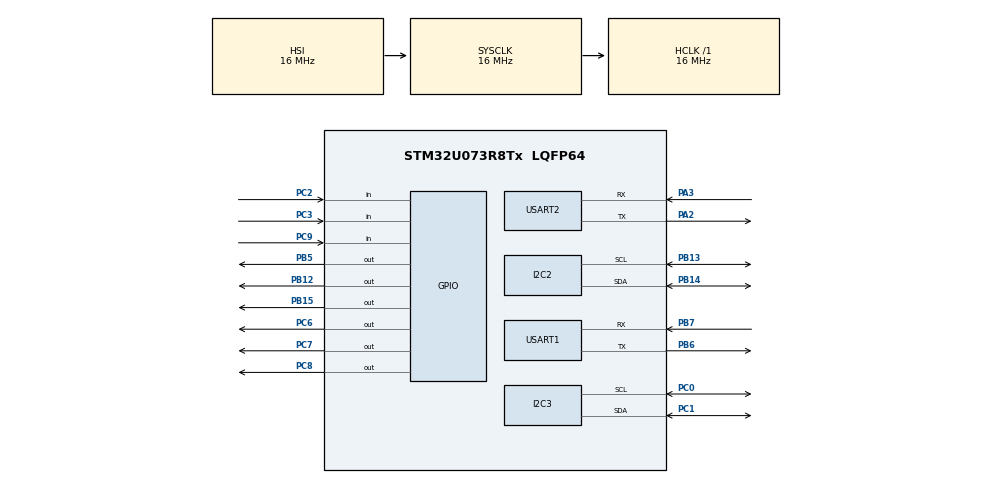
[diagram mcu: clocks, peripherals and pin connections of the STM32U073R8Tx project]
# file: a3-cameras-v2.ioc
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I2C2.Timing=0x00303D5B
I2C3.Timing=0x00303D5B
Mcu.Family=STM32U0
Mcu.Name=STM32U073R8Tx
Mcu.Package=LQFP64
NVIC.PriorityGroup=NVIC_PRIORITYGROUP_2
NVIC.TIM1_BRK_UP_TRG_COM_IRQn=true\:3\:0\:false\:false\:true\:false\:false\:true\:true
NVIC.TimeBase=TIM1_BRK_UP_TRG_COM_IRQn
NVIC.TimeBaseIP=TIM1
PA13\ (SWDIO).Mode=Serial_Wire
PA13\ (SWDIO).Signal=DEBUG_JTMS-SWDIO
PA14\ (SWCLK).Mode=Serial_Wire
PA14\ (SWCLK).Signal=DEBUG_JTCK-SWCLK
PA2.Mode=Asynchronous
PA2.Signal=USART2_TX
PA3.Mode=Asynchronous
PA3.Signal=USART2_RX
PB12.Signal=GPIO_Output
PB13.Mode=I2C
PB13.Signal=I2C2_SCL
PB14.Mode=I2C
PB14.Signal=I2C2_SDA
PB15.Signal=GPIO_Output
PB5.Signal=GPIO_Output
PB6.Mode=Asynchronous
PB6.Signal=USART1_TX
PB7.Mode=Asynchronous
PB7.Signal=USART1_RX
PC0.Mode=I2C
PC0.Signal=I2C3_SCL
PC1.Mode=I2C
PC1.Signal=I2C3_SDA
PC2.Signal=GPIO_Input
PC3.Signal=GPIO_Input
PC6.Signal=GPIO_Output
PC7.Signal=GPIO_Output
PC8.Signal=GPIO_Output
PC9.Signal=GPIO_Input
ProjectManager.HeapSize=0x200
ProjectManager.StackSize=0x400
ProjectManager.TargetToolchain=CMake
RCC.AHBFreq_Value=16000000
RCC.CortexFreq_Value=16000000
RCC.HCLKFreq_Value=16000000
RCC.HSE_VALUE=4000000
RCC.HSI48_VALUE=48000000
RCC.HSI_VALUE=16000000
RCC.LSE_VALUE=32768
RCC.MSI_VALUE=4000000
RCC.SYSCLKFreq_VALUE=16000000
RCC.VCOOutputFreq_Value=64000000
USART1.VirtualMode-Asynchronous=VM_ASYNC
USART2.VirtualMode-Asynchronous=VM_ASYNC
VP_PWR_VS_SECSignals.Mode=Security/Privilege
VP_SYS_VS_tim1.Mode=TIM1
VP_THREADX_VS_RTOSJjThreadXJjCoreJjDefault.Mode=Core_Default
board=custom

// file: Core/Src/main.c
/* USER CODE BEGIN Header */
/**
  ******************************************************************************
  * @file           : main.c
  * @brief          : Main program body
  ******************************************************************************
  * @attention
  *
  * Copyright (c) 2026 STMicroelectronics.
  * All rights reserved.
  *
  * This software is licensed under terms that can be found in the LICENSE file
  * in the root directory of this software component.
  * If no LICENSE file comes with this software, it is provided AS-IS.
  *
  ******************************************************************************
  */
/* USER CODE END Header */
#include "app_threadx.h"
#include "main.h"

/* USER CODE BEGIN Includes */
#include "common.h"
#include "pmic.h"

/* USER CODE END Includes */

I2C_HandleTypeDef hi2c2;
I2C_HandleTypeDef hi2c3;

UART_HandleTypeDef huart1;
UART_HandleTypeDef huart2;

/* USER CODE BEGIN PV */

LED_Status_T LED_STATUS = LED_NOMINAL;

/* USER CODE END PV */

void SystemClock_Config(void);
static void MX_GPIO_Init(void);
static void MX_I2C2_Init(void);
static void MX_I2C3_Init(void);
static void MX_USART1_UART_Init(void);
static void MX_USART2_UART_Init(void);

/* USER CODE BEGIN 0 */

/* Wrapper so other modules pmic.c can re-init UART1 to solve residual voltage issue */
void soc_uart_reinit(void)
{
    MX_USART1_UART_Init();
}

/* USER CODE END 0 */

int main(void)
{

  /* MCU Configuration--------------------------------------------------------*/

  /* Reset of all peripherals, Initializes the Flash interface and the Systick. */
  HAL_Init();

  /* Configure the system clock */
  SystemClock_Config();

  /* Initialize all configured peripherals */
  MX_GPIO_Init();
  MX_I2C2_Init();
  MX_I2C3_Init();
  MX_USART1_UART_Init();
  MX_USART2_UART_Init();

  MX_ThreadX_Init();

  /* We should never get here as control is now taken by the scheduler */

  /* Infinite loop */
  while (1)
  {

  }
}

void SystemClock_Config(void)
{
  RCC_OscInitTypeDef RCC_OscInitStruct = {0};
  RCC_ClkInitTypeDef RCC_ClkInitStruct = {0};

  /** Configure the main internal regulator output voltage
  */
  HAL_PWREx_ControlVoltageScaling(PWR_REGULATOR_VOLTAGE_SCALE2);

  /** Initializes the RCC Oscillators according to the specified parameters
  * in the RCC_OscInitTypeDef structure.
  */
  RCC_OscInitStruct.OscillatorType = RCC_OSCILLATORTYPE_HSI;
  RCC_OscInitStruct.HSIState = RCC_HSI_ON;
  RCC_OscInitStruct.HSICalibrationValue = RCC_HSICALIBRATION_DEFAULT;
  RCC_OscInitStruct.PLL.PLLState = RCC_PLL_NONE;
  if (HAL_RCC_OscConfig(&RCC_OscInitStruct) != HAL_OK)
  {
    Error_Handler();
  }

  /** Initializes the CPU, AHB and APB buses clocks
  */
  RCC_ClkInitStruct.ClockType = RCC_CLOCKTYPE_HCLK|RCC_CLOCKTYPE_SYSCLK
                              |RCC_CLOCKTYPE_PCLK1;
  RCC_ClkInitStruct.SYSCLKSource = RCC_SYSCLKSOURCE_HSI;
  RCC_ClkInitStruct.AHBCLKDivider = RCC_SYSCLK_DIV1;
  RCC_ClkInitStruct.APB1CLKDivider = RCC_HCLK_DIV1;

  if (HAL_RCC_ClockConfig(&RCC_ClkInitStruct, FLASH_LATENCY_1) != HAL_OK)
  {
    Error_Handler();
  }
}

static void MX_I2C2_Init(void)
{

  hi2c2.Instance = I2C2;
  hi2c2.Init.Timing = 0x00303D5B;
  hi2c2.Init.OwnAddress1 = 0;
  hi2c2.Init.AddressingMode = I2C_ADDRESSINGMODE_7BIT;
  hi2c2.Init.DualAddressMode = I2C_DUALADDRESS_DISABLE;
  hi2c2.Init.OwnAddress2 = 0;
  hi2c2.Init.OwnAddress2Masks = I2C_OA2_NOMASK;
  hi2c2.Init.GeneralCallMode = I2C_GENERALCALL_DISABLE;
  hi2c2.Init.NoStretchMode = I2C_NOSTRETCH_DISABLE;
  if (HAL_I2C_Init(&hi2c2) != HAL_OK)
  {
    Error_Handler();
  }

  /** Configure Analogue filter
  */
  if (HAL_I2CEx_ConfigAnalogFilter(&hi2c2, I2C_ANALOGFILTER_ENABLE) != HAL_OK)
  {
    Error_Handler();
  }

  /** Configure Digital filter
  */
  if (HAL_I2CEx_ConfigDigitalFilter(&hi2c2, 0) != HAL_OK)
  {
    Error_Handler();
  }

}

static void MX_I2C3_Init(void)
{

  hi2c3.Instance = I2C3;
  hi2c3.Init.Timing = 0x00303D5B;
  hi2c3.Init.OwnAddress1 = 0;
  hi2c3.Init.AddressingMode = I2C_ADDRESSINGMODE_7BIT;
  hi2c3.Init.DualAddressMode = I2C_DUALADDRESS_DISABLE;
  hi2c3.Init.OwnAddress2 = 0;
  hi2c3.Init.OwnAddress2Masks = I2C_OA2_NOMASK;
  hi2c3.Init.GeneralCallMode = I2C_GENERALCALL_DISABLE;
  hi2c3.Init.NoStretchMode = I2C_NOSTRETCH_DISABLE;
  if (HAL_I2C_Init(&hi2c3) != HAL_OK)
  {
    Error_Handler();
  }

  /** Configure Analogue filter
  */
  if (HAL_I2CEx_ConfigAnalogFilter(&hi2c3, I2C_ANALOGFILTER_ENABLE) != HAL_OK)
  {
    Error_Handler();
  }

  /** Configure Digital filter
  */
  if (HAL_I2CEx_ConfigDigitalFilter(&hi2c3, 0) != HAL_OK)
  {
    Error_Handler();
  }

}

static void MX_USART1_UART_Init(void)
{

  huart1.Instance = USART1;
  huart1.Init.BaudRate = 115200;
  huart1.Init.WordLength = UART_WORDLENGTH_8B;
  huart1.Init.StopBits = UART_STOPBITS_1;
  huart1.Init.Parity = UART_PARITY_NONE;
  huart1.Init.Mode = UART_MODE_TX_RX;
  huart1.Init.HwFlowCtl = UART_HWCONTROL_NONE;
  huart1.Init.OverSampling = UART_OVERSAMPLING_16;
  huart1.Init.OneBitSampling = UART_ONE_BIT_SAMPLE_DISABLE;
  huart1.Init.ClockPrescaler = UART_PRESCALER_DIV1;
  huart1.AdvancedInit.AdvFeatureInit = UART_ADVFEATURE_NO_INIT;
  if (HAL_UART_Init(&huart1) != HAL_OK)
  {
    Error_Handler();
  }
  if (HAL_UARTEx_SetTxFifoThreshold(&huart1, UART_TXFIFO_THRESHOLD_1_8) != HAL_OK)
  {
    Error_Handler();
  }
  if (HAL_UARTEx_SetRxFifoThreshold(&huart1, UART_RXFIFO_THRESHOLD_1_8) != HAL_OK)
  {
    Error_Handler();
  }
  if (HAL_UARTEx_DisableFifoMode(&huart1) != HAL_OK)
  {
    Error_Handler();
  }

}

static void MX_USART2_UART_Init(void)
{

  huart2.Instance = USART2;
  huart2.Init.BaudRate = 115200;
  huart2.Init.WordLength = UART_WORDLENGTH_8B;
  huart2.Init.StopBits = UART_STOPBITS_1;
  huart2.Init.Parity = UART_PARITY_NONE;
  huart2.Init.Mode = UART_MODE_TX_RX;
  huart2.Init.HwFlowCtl = UART_HWCONTROL_NONE;
  huart2.Init.OverSampling = UART_OVERSAMPLING_16;
  huart2.Init.OneBitSampling = UART_ONE_BIT_SAMPLE_DISABLE;
  huart2.Init.ClockPrescaler = UART_PRESCALER_DIV1;
  huart2.AdvancedInit.AdvFeatureInit = UART_ADVFEATURE_NO_INIT;
  if (HAL_UART_Init(&huart2) != HAL_OK)
  {
    Error_Handler();
  }
  if (HAL_UARTEx_SetTxFifoThreshold(&huart2, UART_TXFIFO_THRESHOLD_1_8) != HAL_OK)
  {
    Error_Handler();
  }
  if (HAL_UARTEx_SetRxFifoThreshold(&huart2, UART_RXFIFO_THRESHOLD_1_8) != HAL_OK)
  {
    Error_Handler();
  }
  if (HAL_UARTEx_DisableFifoMode(&huart2) != HAL_OK)
  {
    Error_Handler();
  }

}

static void MX_GPIO_Init(void)
{
  GPIO_InitTypeDef GPIO_InitStruct = {0};

  /* GPIO Ports Clock Enable */
  __HAL_RCC_GPIOC_CLK_ENABLE();
  __HAL_RCC_GPIOA_CLK_ENABLE();
  __HAL_RCC_GPIOB_CLK_ENABLE();

  /*Configure GPIO pin Output Level */
  HAL_GPIO_WritePin(GPIOB, GPIO_PIN_12|GPIO_PIN_15|GPIO_PIN_5, GPIO_PIN_RESET);

  /*Configure GPIO pin Output Level */
  HAL_GPIO_WritePin(GPIOC, GPIO_PIN_6|GPIO_PIN_7|GPIO_PIN_8, GPIO_PIN_RESET);

  /*Configure GPIO pins : PC2 PC3 PC9 */
  GPIO_InitStruct.Pin = GPIO_PIN_2|GPIO_PIN_3|GPIO_PIN_9;
  GPIO_InitStruct.Mode = GPIO_MODE_INPUT;
  GPIO_InitStruct.Pull = GPIO_NOPULL;
  HAL_GPIO_Init(GPIOC, &GPIO_InitStruct);

  /*Configure GPIO pins : PB12 PB15 PB5 */
  GPIO_InitStruct.Pin = GPIO_PIN_12|GPIO_PIN_15|GPIO_PIN_5;
  GPIO_InitStruct.Mode = GPIO_MODE_OUTPUT_PP;
  GPIO_InitStruct.Pull = GPIO_NOPULL;
  GPIO_InitStruct.Speed = GPIO_SPEED_FREQ_LOW;
  HAL_GPIO_Init(GPIOB, &GPIO_InitStruct);

  /*Configure GPIO pins : PC6 PC7 PC8 */
  GPIO_InitStruct.Pin = GPIO_PIN_6|GPIO_PIN_7|GPIO_PIN_8;
  GPIO_InitStruct.Mode = GPIO_MODE_OUTPUT_PP;
  GPIO_InitStruct.Pull = GPIO_NOPULL;
  GPIO_InitStruct.Speed = GPIO_SPEED_FREQ_LOW;
  HAL_GPIO_Init(GPIOC, &GPIO_InitStruct);

}

void HAL_TIM_PeriodElapsedCallback(TIM_HandleTypeDef *htim)
{
  if (htim->Instance == TIM1)
  {
    HAL_IncTick();
  }
}

void Error_Handler(void)
{
  __disable_irq();
  while (1)
  {
  }
}
